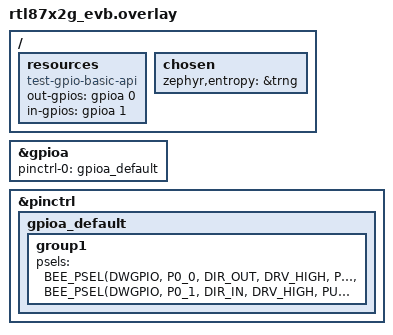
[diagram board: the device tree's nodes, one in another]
/*
 * Copyright(c) 2025, Realtek Semiconductor Corporation.
 *
 * SPDX-License-Identifier: Apache-2.0
 */

#include <zephyr/dt-bindings/gpio/realtek-bee-gpio.h>

&gpioa {
	pinctrl-0 = <&gpioa_default>;
	pinctrl-names = "default";
	status = "okay";
};

/ {
	resources {
		compatible = "test-gpio-basic-api";
		out-gpios = <&gpioa 0 GPIO_ACTIVE_HIGH>;
		in-gpios = <&gpioa 1 (GPIO_ACTIVE_HIGH | BEE_GPIO_INPUT_DEBOUNCE_MS(8))>;
	};

	chosen {
		zephyr,entropy = &trng;
	};
};

&pinctrl {
	gpioa_default: gpioa_default {
		group1 {
			psels = <BEE_PSEL(DWGPIO, P0_0, DIR_OUT, DRV_HIGH, PULL_UP)>,
			<BEE_PSEL(DWGPIO, P0_1, DIR_IN, DRV_HIGH, PULL_UP)>;
		};
	};
};
